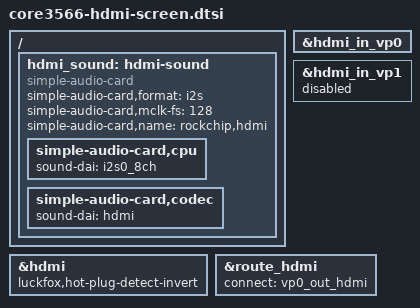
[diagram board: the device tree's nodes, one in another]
// SPDX-License-Identifier: (GPL-2.0+ OR MIT)
/*
 * Copyright (c) 2023 luckfox technology Limited.
 */

/ {
	hdmi_sound: hdmi-sound {
		compatible = "simple-audio-card";
		simple-audio-card,format = "i2s";
		simple-audio-card,mclk-fs = <128>;
		simple-audio-card,name = "rockchip,hdmi";

		simple-audio-card,cpu {
				sound-dai = <&i2s0_8ch>;
		};
		simple-audio-card,codec {
				sound-dai = <&hdmi>;
		};
	};
};

&hdmi {
	status = "okay";
	luckfox,hot-plug-detect-invert;
};

&hdmi_in_vp0 {
	status = "okay";
};

&hdmi_in_vp1 {
	status = "disabled";
};

&hdmi_sound {
	status = "okay";
};

&route_hdmi {
	status = "okay";
	connect = <&vp0_out_hdmi>;
};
